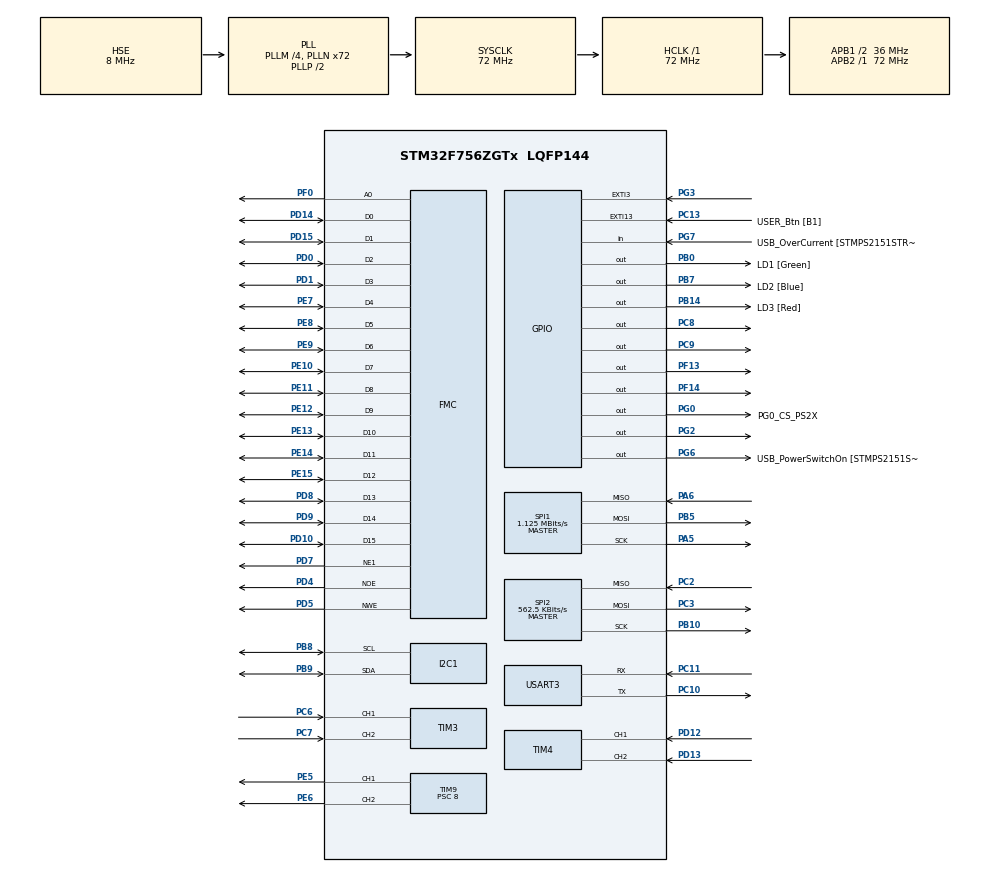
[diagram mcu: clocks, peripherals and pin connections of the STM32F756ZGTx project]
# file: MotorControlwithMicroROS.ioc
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CORTEX_M7.default_mode_Activation=1
Dma.Request0=USART3_RX
Dma.Request1=USART3_TX
Dma.USART3_RX.0.Direction=DMA_PERIPH_TO_MEMORY
Dma.USART3_RX.0.FIFOMode=DMA_FIFOMODE_DISABLE
Dma.USART3_RX.0.Instance=DMA1_Stream1
Dma.USART3_RX.0.MemDataAlignment=DMA_MDATAALIGN_BYTE
Dma.USART3_RX.0.MemInc=DMA_MINC_ENABLE
Dma.USART3_RX.0.Mode=DMA_CIRCULAR
Dma.USART3_RX.0.PeriphDataAlignment=DMA_PDATAALIGN_BYTE
Dma.USART3_RX.0.PeriphInc=DMA_PINC_DISABLE
Dma.USART3_RX.0.Priority=DMA_PRIORITY_VERY_HIGH
Dma.USART3_TX.1.Direction=DMA_MEMORY_TO_PERIPH
Dma.USART3_TX.1.FIFOMode=DMA_FIFOMODE_DISABLE
Dma.USART3_TX.1.Instance=DMA1_Stream3
Dma.USART3_TX.1.MemDataAlignment=DMA_MDATAALIGN_BYTE
Dma.USART3_TX.1.MemInc=DMA_MINC_ENABLE
Dma.USART3_TX.1.Mode=DMA_NORMAL
Dma.USART3_TX.1.PeriphDataAlignment=DMA_PDATAALIGN_BYTE
Dma.USART3_TX.1.PeriphInc=DMA_PINC_DISABLE
Dma.USART3_TX.1.Priority=DMA_PRIORITY_VERY_HIGH
FMC.AddressSetupTime1=1
FMC.BusTurnAroundDuration1=0
FMC.DataSetupTime1=5
FREERTOS.Tasks01=defaultTask,24,3000,StartDefaultTask,Default,NULL,Dynamic,NULL,NULL
FREERTOS.configTOTAL_HEAP_SIZE=61440
I2C1.Timing=0x00808CD2
Mcu.Family=STM32F7
Mcu.Name=STM32F756ZGTx
Mcu.Package=LQFP144
NVIC.DMA1_Stream1_IRQn=true\:5\:0\:false\:false\:true\:true\:false\:true\:true
NVIC.DMA1_Stream3_IRQn=true\:5\:0\:false\:false\:true\:true\:false\:true\:true
NVIC.EXTI3_IRQn=true\:5\:0\:false\:false\:true\:true\:true\:true\:true
NVIC.PriorityGroup=NVIC_PRIORITYGROUP_4
NVIC.TIM6_DAC_IRQn=true\:15\:0\:false\:false\:true\:false\:false\:true\:true
NVIC.TimeBase=TIM6_DAC_IRQn
NVIC.TimeBaseIP=TIM6
NVIC.USART3_IRQn=true\:5\:0\:false\:false\:true\:true\:true\:true\:true
PA13.GPIO_Label=TMS
PA13.Mode=Serial_Wire
PA13.Signal=SYS_JTMS-SWDIO
PA14.GPIO_Label=TCK
PA14.Mode=Serial_Wire
PA14.Signal=SYS_JTCK-SWCLK
PA5.Mode=Full_Duplex_Master
PA5.Signal=SPI1_SCK
PA6.Mode=Full_Duplex_Master
PA6.Signal=SPI1_MISO
PA7.GPIO_Label=RMII_CRS_DV [LAN8742A-CZ-TR_CRS_DV]
PA7.Signal=ETH_CRS_DV
PB0.GPIO_Label=LD1 [Green]
PB0.Signal=GPIO_Output
PB10.Mode=Full_Duplex_Master
PB10.Signal=SPI2_SCK
PB13.GPIO_Label=RMII_TXD1 [LAN8742A-CZ-TR_TXD1]
PB13.Signal=ETH_TXD1
PB14.GPIO_Label=LD3 [Red]
PB14.Signal=GPIO_Output
PB3.GPIO_Label=SW0
PB3.Signal=SYS_JTDO-SWO
PB5.Mode=Full_Duplex_Master
PB5.Signal=SPI1_MOSI
PB7.GPIO_Label=LD2 [Blue]
PB7.Signal=GPIO_Output
PB8.Mode=I2C
PB8.Signal=I2C1_SCL
PB9.Mode=I2C
PB9.Signal=I2C1_SDA
PC1.GPIO_Label=RMII_MDC [LAN8742A-CZ-TR_MDC]
PC1.Signal=ETH_MDC
PC10.Mode=Asynchronous
PC10.Signal=USART3_TX
PC11.Mode=Asynchronous
PC11.Signal=USART3_RX
PC13.GPIO_Label=USER_Btn [B1]
PC13.Signal=GPXTI13
PC14/OSC32_IN.Mode=LSE-External-Oscillator
PC14/OSC32_IN.Signal=RCC_OSC32_IN
PC15/OSC32_OUT.Mode=LSE-External-Oscillator
PC15/OSC32_OUT.Signal=RCC_OSC32_OUT
PC2.Mode=Full_Duplex_Master
PC2.Signal=SPI2_MISO
PC3.Mode=Full_Duplex_Master
PC3.Signal=SPI2_MOSI
PC4.GPIO_Label=RMII_RXD0 [LAN8742A-CZ-TR_RXD0]
PC4.Signal=ETH_RXD0
PC5.GPIO_Label=RMII_RXD1 [LAN8742A-CZ-TR_RXD1]
PC5.Signal=ETH_RXD1
PC6.GPIO_ModeDefaultPP=GPIO_MODE_AF_PP
PC6.GPIO_PuPd=GPIO_NOPULL
PC6.Signal=S_TIM3_CH1
PC7.GPIO_ModeDefaultPP=GPIO_MODE_AF_PP
PC7.GPIO_PuPd=GPIO_NOPULL
PC7.Signal=S_TIM3_CH2
PC8.Signal=GPIO_Output
PC9.Signal=GPIO_Output
PD0.Signal=FMC_D2_DA2
PD1.Signal=FMC_D3_DA3
PD10.Signal=FMC_D15_DA15
PD12.Signal=S_TIM4_CH1
PD13.Signal=S_TIM4_CH2
PD14.Signal=FMC_D0_DA0
PD15.Signal=FMC_D1_DA1
PD4.Signal=FMC_NOE
PD5.Signal=FMC_NWE
PD7.Mode=NorPsramChipSelect1_1
PD7.Signal=FMC_NE1
PD8.Signal=FMC_D13_DA13
PD9.Signal=FMC_D14_DA14
PE10.Signal=FMC_D7_DA7
PE11.Signal=FMC_D8_DA8
PE12.Signal=FMC_D9_DA9
PE13.Signal=FMC_D10_DA10
PE14.Signal=FMC_D11_DA11
PE15.Signal=FMC_D12_DA12
PE5.Signal=S_TIM9_CH1
PE6.Signal=S_TIM9_CH2
PE7.Signal=FMC_D4_DA4
PE8.Signal=FMC_D5_DA5
PE9.Signal=FMC_D6_DA6
PF0.Signal=FMC_A0
PF13.Signal=GPIO_Output
PF14.Signal=GPIO_Output
PG0.GPIO_Label=PG0_CS_PS2X
PG0.GPIO_ModeDefaultOutputPP=GPIO_MODE_OUTPUT_PP
PG0.GPIO_Speed=GPIO_SPEED_FREQ_HIGH
PG0.PinState=GPIO_PIN_SET
PG0.Signal=GPIO_Output
PG11.GPIO_Label=RMII_TX_EN [LAN8742A-CZ-TR_TXEN]
PG11.Signal=ETH_TX_EN
PG2.GPIO_Speed=GPIO_SPEED_FREQ_LOW
PG2.PinState=GPIO_PIN_SET
PG2.Signal=GPIO_Output
PG3.GPIO_ModeDefaultEXTI=GPIO_MODE_IT_FALLING
PG3.GPIO_PuPd=GPIO_PULLUP
PG3.Signal=GPXTI3
PG6.GPIO_Label=USB_PowerSwitchOn [STMPS2151STR_EN]
PG6.Signal=GPIO_Output
PG7.GPIO_Label=USB_OverCurrent [STMPS2151STR_FAULT]
PG7.Signal=GPIO_Input
PH0/OSC_IN.GPIO_Label=MCO [STM32F103CBT6_PA8]
PH0/OSC_IN.Mode=HSE-External-Oscillator
PH0/OSC_IN.Signal=RCC_OSC_IN
PH1/OSC_OUT.Mode=HSE-External-Oscillator
PH1/OSC_OUT.Signal=RCC_OSC_OUT
ProjectManager.HeapSize=0x200
ProjectManager.StackSize=0x400
ProjectManager.TargetToolchain=Makefile
RCC.48MHZClocksFreq_Value=24000000
RCC.AHBFreq_Value=72000000
RCC.APB1CLKDivider=RCC_HCLK_DIV2
RCC.APB1Freq_Value=36000000
RCC.APB1TimFreq_Value=72000000
RCC.APB2Freq_Value=72000000
RCC.APB2TimFreq_Value=72000000
RCC.CortexFreq_Value=72000000
RCC.HCLKFreq_Value=72000000
RCC.HSE_VALUE=8000000
RCC.HSI_VALUE=16000000
RCC.PLLM=4
RCC.PLLMUL=RCC_PLL_MUL9
RCC.PLLN=72
RCC.PLLQ=3
RCC.PLLSourceVirtual=RCC_PLLSOURCE_HSE
RCC.PRESCALERUSB=RCC_USBCLKSOURCE_PLL_DIV1_5
RCC.SYSCLKFreq_VALUE=72000000
RCC.SYSCLKSource=RCC_SYSCLKSOURCE_PLLCLK
RCC.SYSCLKSourceVirtual=RCC_SYSCLKSOURCE_PLLCLK
RCC.USBFreq_Value=48000000
RCC.VCOOutputFreq_Value=144000000
SH.FMC_A0.0=FMC_A0,A0_1
SH.FMC_D0_DA0.0=FMC_D0,16b-d1
SH.FMC_D10_DA10.0=FMC_D10,16b-d1
SH.FMC_D11_DA11.0=FMC_D11,16b-d1
SH.FMC_D12_DA12.0=FMC_D12,16b-d1
SH.FMC_D13_DA13.0=FMC_D13,16b-d1
SH.FMC_D14_DA14.0=FMC_D14,16b-d1
SH.FMC_D15_DA15.0=FMC_D15,16b-d1
SH.FMC_D1_DA1.0=FMC_D1,16b-d1
SH.FMC_D2_DA2.0=FMC_D2,16b-d1
SH.FMC_D3_DA3.0=FMC_D3,16b-d1
SH.FMC_D4_DA4.0=FMC_D4,16b-d1
SH.FMC_D5_DA5.0=FMC_D5,16b-d1
SH.FMC_D6_DA6.0=FMC_D6,16b-d1
SH.FMC_D7_DA7.0=FMC_D7,16b-d1
SH.FMC_D8_DA8.0=FMC_D8,16b-d1
SH.FMC_D9_DA9.0=FMC_D9,16b-d1
SH.FMC_NOE.0=FMC_NOE,Lcd1
SH.FMC_NWE.0=FMC_NWE,Lcd1
SH.S_TIM3_CH1.0=TIM3_CH1,Encoder_Interface
SH.S_TIM3_CH2.0=TIM3_CH2,Encoder_Interface
SH.S_TIM4_CH1.0=TIM4_CH1,Encoder_Interface
SH.S_TIM4_CH2.0=TIM4_CH2,Encoder_Interface
SH.S_TIM9_CH1.0=TIM9_CH1,PWM Generation1 CH1
SH.S_TIM9_CH2.0=TIM9_CH2,PWM Generation2 CH2
SPI1.BaudRatePrescaler=SPI_BAUDRATEPRESCALER_64
SPI1.CalculateBaudRate=1.125 MBits/s
SPI1.DataSize=SPI_DATASIZE_8BIT
SPI1.Direction=SPI_DIRECTION_2LINES
SPI1.Mode=SPI_MODE_MASTER
SPI1.VirtualType=VM_MASTER
SPI2.BaudRatePrescaler=SPI_BAUDRATEPRESCALER_64
SPI2.CLKPhase=SPI_PHASE_2EDGE
SPI2.CLKPolarity=SPI_POLARITY_HIGH
SPI2.CalculateBaudRate=562.5 KBits/s
SPI2.DataSize=SPI_DATASIZE_8BIT
SPI2.Direction=SPI_DIRECTION_2LINES
SPI2.FirstBit=SPI_FIRSTBIT_LSB
SPI2.Mode=SPI_MODE_MASTER
SPI2.VirtualType=VM_MASTER
TIM3.AutoReloadPreload=TIM_AUTORELOAD_PRELOAD_ENABLE
TIM3.EncoderMode=TIM_ENCODERMODE_TI12
TIM3.IC1Filter=6
TIM3.IC2Filter=6
TIM4.AutoReloadPreload=TIM_AUTORELOAD_PRELOAD_ENABLE
TIM4.EncoderMode=TIM_ENCODERMODE_TI12
TIM4.IC1Filter=6
TIM4.IC2Filter=6
TIM9.Channel-PWM\ Generation1\ CH1=TIM_CHANNEL_1
TIM9.Channel-PWM\ Generation2\ CH2=TIM_CHANNEL_2
TIM9.Period=1199
TIM9.Prescaler=8
USART3.VirtualMode-Asynchronous=VM_ASYNC
VP_FREERTOS_VS_CMSIS_V2.Mode=CMSIS_V2
VP_SYS_VS_tim6.Mode=TIM6
VP_TIM9_VS_ClockSourceINT.Mode=Internal
board=NUCLEO-F756ZG

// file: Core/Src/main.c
/* USER CODE BEGIN Header */
/**
  ******************************************************************************
  * @file           : main.c
  * @brief          : Main program body
  ******************************************************************************
  * @attention
  *
  * Copyright (c) 2025 STMicroelectronics.
  * All rights reserved.
  *
  * This software is licensed under terms that can be found in the LICENSE file
  * in the root directory of this software component.
  * If no LICENSE file comes with this software, it is provided AS-IS.
  *
  ******************************************************************************
  */
/* USER CODE END Header */
#include "main.h"
#include "cmsis_os.h"
#include "dma.h"
#include "i2c.h"
#include "spi.h"
#include "tim.h"
#include "usart.h"
#include "gpio.h"
#include "fmc.h"

/* USER CODE BEGIN Includes */
#include "robot_params.h"
#include "encoder.h"
#include "motor.h"
#include "encoder_speed.h"
#include "pid.h"
#include "odometry.h"
#include "ili9341.h"
#include "xpt2046.h"
#include "touch_event.h"
#include "ps2xlib.h"
#include <stdarg.h>
#include <stdio.h>
#include <stdbool.h>

//#include "usb_otg_host.h"
/* USER CODE END Includes */

/* USER CODE BEGIN PTD */
#define min(a,b) (((a)<(b))?(a):(b))
/* USER CODE END PTD */

void SystemClock_Config(void);
static void MPU_Config(void);
void MX_FREERTOS_Init(void);
/* USER CODE BEGIN PFP */
void demoLCD(int i);
void locLCD(void);
unsigned long testFillScreen();
unsigned long testText();
unsigned long testLines(uint16_t color);
unsigned long testFastLines(uint16_t color1, uint16_t color2);
unsigned long testRects(uint16_t color);
unsigned long testFilledRects(uint16_t color1, uint16_t color2);
unsigned long testFilledCircles(uint8_t radius, uint16_t color);
unsigned long testCircles(uint8_t radius, uint16_t color);
unsigned long testTriangles();
unsigned long testFilledTriangles();
unsigned long testRoundRects();
unsigned long testFilledRoundRects();
unsigned long testDrawImage();
/* USER CODE END PFP */

int main(void)
{

  /* MPU Configuration--------------------------------------------------------*/
  MPU_Config();

  /* MCU Configuration--------------------------------------------------------*/

  /* Reset of all peripherals, Initializes the Flash interface and the Systick. */
  HAL_Init();

  /* Configure the system clock */
  SystemClock_Config();

  /* Initialize all configured peripherals */
  MX_GPIO_Init();
  MX_DMA_Init();
  MX_I2C1_Init();
  MX_USART3_UART_Init();
  MX_TIM3_Init();
  MX_TIM9_Init();
  MX_FMC_Init();
  MX_SPI1_Init();
  MX_SPI2_Init();
  MX_TIM4_Init();
  /* USER CODE BEGIN 2 */
  //HAL_NVIC_DisableIRQ(TIM6_DAC_IRQn);  //tam dung ngat timer 6 de setup
  //MX_USB_OTG_FS_HCD_Init();
  //MX_USB_HOST_Init();
  //HAL_NVIC_EnableIRQ(TIM6_DAC_IRQn);   //bat lai ngat timer 6

  HAL_GPIO_WritePin(GPIOC, GPIO_PIN_8, GPIO_PIN_RESET); // RESET = 0
  HAL_Delay(10);
  HAL_GPIO_WritePin(GPIOC, GPIO_PIN_8, GPIO_PIN_SET);   // RESET = 1
  HAL_Delay(120);

  //Initialize touch event
  //Touch_Init_Lib();

  Encoder_Reset(ENCODER_1);
  Encoder_Reset(ENCODER_2);
  Encoder_Init();
  EncoderSpeed_Init();
  Motor_Init();

  //int32_t PID_sampletime = 5;

  PID(&PosPID1, &CurPos1, &PosPIDOut1, &DesiredPos1, Kp1, Ki1, Kd1, _PID_P_ON_E, _PID_CD_DIRECT);
  PID_SetMode(&PosPID1, _PID_MODE_AUTOMATIC);
  PID_SetSampleTime(&PosPID1, MOTORCONTROL_PERIOD_MS);
  PID_SetOutputLimits(&PosPID1, -MOTOR_SPEED_MAX, MOTOR_SPEED_MAX);

  PID(&PosPID2, &CurPos2, &PosPIDOut2, &DesiredPos2, Kp2, Ki2, Kd2, _PID_P_ON_E, _PID_CD_DIRECT);
  PID_SetMode(&PosPID2, _PID_MODE_AUTOMATIC);
  PID_SetSampleTime(&PosPID2, MOTORCONTROL_PERIOD_MS);
  PID_SetOutputLimits(&PosPID2, -MOTOR_SPEED_MAX, MOTOR_SPEED_MAX);

  PID(&SpeedPID1, &CurSpeed1, &SpeedPIDOut1, &DesiredSpeed1, Kp1, Ki1, Kd1, _PID_P_ON_E, _PID_CD_DIRECT);
  PID_SetMode(&SpeedPID1, _PID_MODE_AUTOMATIC);
  PID_SetSampleTime(&SpeedPID1, MOTORCONTROL_PERIOD_MS);
  PID_SetOutputLimits(&SpeedPID1, -MOTOR_SPEED_MAX, MOTOR_SPEED_MAX);

  PID(&SpeedPID2, &CurSpeed2, &SpeedPIDOut2, &DesiredSpeed2, Kp2, Ki2, Kd2, _PID_P_ON_E, _PID_CD_DIRECT);
  PID_SetMode(&SpeedPID2, _PID_MODE_AUTOMATIC);
  PID_SetSampleTime(&SpeedPID2, MOTORCONTROL_PERIOD_MS);
  PID_SetOutputLimits(&SpeedPID2, -MOTOR_SPEED_MAX, MOTOR_SPEED_MAX);

  PID_Init(&PosPID1); PID_Init(&PosPID2);
  PID_Init(&SpeedPID1); PID_Init(&SpeedPID2);

  //Here start to display LCD
  lcdInit();
  int i = 1;
  for (i=0;i<=0;i++)
  {
	  //demoLCD(i);
	  locLCD();

  }

//  const char test_msg[] = "USART2 VCP OK\r\n";
//  while (1)
//  {
//	  HAL_StatusTypeDef st = HAL_UART_Transmit(&huart2,
//	                                           (uint8_t*)test_msg,
//	                                           sizeof(test_msg)-1,
//	                                           10);
//
//    HAL_Delay(500);   // gửi mỗi 500 ms
//  }
  /* USER CODE END 2 */

  /* Init scheduler */
  osKernelInitialize();  /* Call init function for freertos objects (in cmsis_os2.c) */
  MX_FREERTOS_Init();

  /* Start scheduler */
  osKernelStart();

  /* We should never get here as control is now taken by the scheduler */

  /* Infinite loop */
  while (1)
  {

  }
}

void SystemClock_Config(void)
{
  RCC_OscInitTypeDef RCC_OscInitStruct = {0};
  RCC_ClkInitTypeDef RCC_ClkInitStruct = {0};

  /** Configure LSE Drive Capability
  */
  HAL_PWR_EnableBkUpAccess();

  /** Configure the main internal regulator output voltage
  */
  __HAL_RCC_PWR_CLK_ENABLE();
  __HAL_PWR_VOLTAGESCALING_CONFIG(PWR_REGULATOR_VOLTAGE_SCALE3);

  /** Initializes the RCC Oscillators according to the specified parameters
  * in the RCC_OscInitTypeDef structure.
  */
  RCC_OscInitStruct.OscillatorType = RCC_OSCILLATORTYPE_HSE;
  RCC_OscInitStruct.HSEState = RCC_HSE_ON;
  RCC_OscInitStruct.PLL.PLLState = RCC_PLL_ON;
  RCC_OscInitStruct.PLL.PLLSource = RCC_PLLSOURCE_HSE;
  RCC_OscInitStruct.PLL.PLLM = 4;
  RCC_OscInitStruct.PLL.PLLN = 72;
  RCC_OscInitStruct.PLL.PLLP = RCC_PLLP_DIV2;
  RCC_OscInitStruct.PLL.PLLQ = 3;
  if (HAL_RCC_OscConfig(&RCC_OscInitStruct) != HAL_OK)
  {
    Error_Handler();
  }

  /** Initializes the CPU, AHB and APB buses clocks
  */
  RCC_ClkInitStruct.ClockType = RCC_CLOCKTYPE_HCLK|RCC_CLOCKTYPE_SYSCLK
                              |RCC_CLOCKTYPE_PCLK1|RCC_CLOCKTYPE_PCLK2;
  RCC_ClkInitStruct.SYSCLKSource = RCC_SYSCLKSOURCE_PLLCLK;
  RCC_ClkInitStruct.AHBCLKDivider = RCC_SYSCLK_DIV1;
  RCC_ClkInitStruct.APB1CLKDivider = RCC_HCLK_DIV2;
  RCC_ClkInitStruct.APB2CLKDivider = RCC_HCLK_DIV1;

  if (HAL_RCC_ClockConfig(&RCC_ClkInitStruct, FLASH_LATENCY_2) != HAL_OK)
  {
    Error_Handler();
  }
}

/* USER CODE BEGIN 4 */
void MPU_Config(void)
{
  MPU_Region_InitTypeDef MPU_InitStruct = {0};

  HAL_MPU_Disable();

  // -------- Region0: default deny (giữ giống bạn) --------
  MPU_InitStruct.Enable           = MPU_REGION_ENABLE;
  MPU_InitStruct.Number           = MPU_REGION_NUMBER0;
  MPU_InitStruct.BaseAddress      = 0x00000000;
  MPU_InitStruct.Size             = MPU_REGION_SIZE_4GB;
  MPU_InitStruct.SubRegionDisable = 0x87; // như bạn
  MPU_InitStruct.TypeExtField     = MPU_TEX_LEVEL0;
  MPU_InitStruct.AccessPermission = MPU_REGION_NO_ACCESS;
  MPU_InitStruct.DisableExec      = MPU_INSTRUCTION_ACCESS_DISABLE;
  MPU_InitStruct.IsShareable      = MPU_ACCESS_SHAREABLE;
  MPU_InitStruct.IsCacheable      = MPU_ACCESS_NOT_CACHEABLE;
  MPU_InitStruct.IsBufferable     = MPU_ACCESS_NOT_BUFFERABLE;
  HAL_MPU_ConfigRegion(&MPU_InitStruct);

  // -------- Region1: allow FMC registers @0xA0000000 --------
  MPU_InitStruct.Enable           = MPU_REGION_ENABLE;
  MPU_InitStruct.Number           = MPU_REGION_NUMBER1;
  MPU_InitStruct.BaseAddress      = 0xA0000000;
  MPU_InitStruct.Size             = MPU_REGION_SIZE_1MB;   // đủ cho FMC regs
  MPU_InitStruct.SubRegionDisable = 0x00;
  MPU_InitStruct.TypeExtField     = MPU_TEX_LEVEL0;
  MPU_InitStruct.AccessPermission = MPU_REGION_FULL_ACCESS;
  MPU_InitStruct.DisableExec      = MPU_INSTRUCTION_ACCESS_DISABLE;
  MPU_InitStruct.IsShareable      = MPU_ACCESS_SHAREABLE;
  MPU_InitStruct.IsCacheable      = MPU_ACCESS_NOT_CACHEABLE;
  MPU_InitStruct.IsBufferable     = MPU_ACCESS_BUFFERABLE; // peripheral/device
  HAL_MPU_ConfigRegion(&MPU_InitStruct);

  // -------- Region2: allow FMC Bank1 mapped @0x60000000 (LCD) --------
  MPU_InitStruct.Enable           = MPU_REGION_ENABLE;
  MPU_InitStruct.Number           = MPU_REGION_NUMBER2;
  MPU_InitStruct.BaseAddress      = 0x60000000;
  MPU_InitStruct.Size             = MPU_REGION_SIZE_64MB;  // Bank1 window (thường dùng)
  MPU_InitStruct.SubRegionDisable = 0x00;
  MPU_InitStruct.TypeExtField     = MPU_TEX_LEVEL0;
  MPU_InitStruct.AccessPermission = MPU_REGION_FULL_ACCESS;
  MPU_InitStruct.DisableExec      = MPU_INSTRUCTION_ACCESS_DISABLE;
  MPU_InitStruct.IsShareable      = MPU_ACCESS_SHAREABLE;
  MPU_InitStruct.IsCacheable      = MPU_ACCESS_NOT_CACHEABLE;
  MPU_InitStruct.IsBufferable     = MPU_ACCESS_BUFFERABLE;
  HAL_MPU_ConfigRegion(&MPU_InitStruct);

  HAL_MPU_Enable(MPU_PRIVILEGED_DEFAULT);
}

void demoLCD(int i)
{
	lcdSetOrientation(i % 4);

	uint32_t t = testFillScreen();
	lcdSetTextFont(&Font16);
	lcdSetCursor(0, lcdGetHeight() - lcdGetTextFont()->Height - 1);
	lcdSetTextColor(COLOR_WHITE, COLOR_BLACK);
	lcdPrintf("Time: %4lu ms", t);
	HAL_Delay(2000);

	t = HAL_GetTick();
	lcdTest();
	lcdSetTextFont(&Font16);
	lcdSetCursor(0, lcdGetHeight() - lcdGetTextFont()->Height - 1);
	lcdSetTextColor(COLOR_WHITE, COLOR_BLACK);
	lcdPrintf("Time: %4lu ms", HAL_GetTick() - t);
	HAL_Delay(2000);

	t = testText();
	lcdSetTextFont(&Font16);
	lcdSetCursor(0, lcdGetHeight() - lcdGetTextFont()->Height - 1);
	lcdSetTextColor(COLOR_WHITE, COLOR_BLACK);
	lcdPrintf("Time: %4lu ms", t);
	HAL_Delay(2000);

	lcdSetTextFont(&Font16);
	lcdSetCursor(0, lcdGetHeight() - lcdGetTextFont()->Height - 1);
	lcdSetTextColor(COLOR_WHITE, COLOR_BLACK);
	lcdPrintf("Time: %4lu ms", testLines(COLOR_CYAN));
	HAL_Delay(2000);

	lcdSetTextFont(&Font16);
	lcdSetCursor(0, lcdGetHeight() - lcdGetTextFont()->Height - 1);
	lcdSetTextColor(COLOR_WHITE, COLOR_BLACK);
	lcdPrintf("Time: %4lu ms", testFastLines(COLOR_RED, COLOR_BLUE));
	HAL_Delay(2000);

	lcdSetTextFont(&Font16);
	lcdSetCursor(0, lcdGetHeight() - lcdGetTextFont()->Height - 1);
	lcdSetTextColor(COLOR_WHITE, COLOR_BLACK);
	lcdPrintf("Time: %4lu ms", testRects(COLOR_GREEN));
	HAL_Delay(2000);

	lcdSetTextFont(&Font16);
	lcdSetCursor(0, lcdGetHeight() - lcdGetTextFont()->Height - 1);
	lcdSetTextColor(COLOR_WHITE, COLOR_BLACK);
	lcdPrintf("Time: %4lu ms", testFilledRects(COLOR_YELLOW, COLOR_MAGENTA));
	HAL_Delay(2000);

	lcdSetTextFont(&Font16);
	lcdSetCursor(0, lcdGetHeight() - lcdGetTextFont()->Height - 1);
	lcdSetTextColor(COLOR_WHITE, COLOR_BLACK);
	lcdPrintf("Time: %4lu ms", testFilledCircles(10, COLOR_MAGENTA));
	HAL_Delay(2000);

	lcdSetTextFont(&Font16);
	lcdSetCursor(0, lcdGetHeight() - lcdGetTextFont()->Height - 1);
	lcdSetTextColor(COLOR_WHITE, COLOR_BLACK);
	lcdPrintf("Time: %4lu ms", testCircles(10, COLOR_WHITE));
	HAL_Delay(2000);

	lcdSetTextFont(&Font16);
	lcdSetCursor(0, lcdGetHeight() - lcdGetTextFont()->Height - 1);
	lcdSetTextColor(COLOR_WHITE, COLOR_BLACK);
	lcdPrintf("Time: %4lu ms", testTriangles());
	HAL_Delay(2000);

	lcdSetTextFont(&Font16);
	lcdSetCursor(0, lcdGetHeight() - lcdGetTextFont()->Height - 1);
	lcdSetTextColor(COLOR_WHITE, COLOR_BLACK);
	lcdPrintf("Time: %4lu ms", testFilledTriangles());
	HAL_Delay(2000);

	lcdSetTextFont(&Font16);
	lcdSetCursor(0, lcdGetHeight() - lcdGetTextFont()->Height - 1);
	lcdSetTextColor(COLOR_WHITE, COLOR_BLACK);
	lcdPrintf("Time: %4lu ms", testRoundRects());
	HAL_Delay(2000);

	lcdSetTextFont(&Font16);
	lcdSetCursor(0, lcdGetHeight() - lcdGetTextFont()->Height - 1);
	lcdSetTextColor(COLOR_WHITE, COLOR_BLACK);
	lcdPrintf("Time: %4lu ms", testFilledRoundRects());
	HAL_Delay(2000);

	lcdSetTextFont(&Font16);
	lcdSetCursor(0, lcdGetHeight() - lcdGetTextFont()->Height - 1);
	lcdSetTextColor(COLOR_WHITE, COLOR_BLACK);
	lcdPrintf("Time: %4lu ms", testDrawImage());
	HAL_Delay(2000);
}

typedef struct { uint16_t x,y,w,h; } Rect_t;

static Rect_t g_val_pwm1, g_val_pwm2, g_val_enc1, g_val_enc2;
static Rect_t g_val_v1, g_val_v2;
static Rect_t g_val_x, g_val_y, g_val_yaw;

static uint16_t g_charW = 8, g_fontH = 12, g_pad = 6;

void locLCD(void)
{
    lcdSetOrientation(LCD_ORIENTATION_LANDSCAPE);
    lcdFillRGB(COLOR_BLACK);
    lcdSetTextFont(&Font12);

    uint16_t W = lcdGetWidth();
    uint16_t H = lcdGetHeight();

    uint16_t fontH = lcdGetTextFont()->Height;
    uint16_t charW = lcdGetTextFont()->Width;   // nếu lỗi -> đổi thành 8

    // ===== Grid =====
    uint16_t M  = 6;
    uint16_t GX = M;
    uint16_t GY = 22;
    uint16_t GW = W - 2*M;
    uint16_t GH = H - GY - M;

    uint16_t CW = GW / 3;
    uint16_t RH = GH / 4;
    uint16_t P  = 6;
    g_fontH = fontH;
    g_charW = (charW == 0) ? 8 : charW;
    g_pad   = P;

    #define STORE_VALUE_RECT(_rect, cx, cy, cw, ch) do {                          \
        int16_t _y0 = (int16_t)(cy) + (int16_t)(((ch) - 2*(int16_t)fontH)/2);     \
        if (_y0 < (int16_t)(cy)+P) _y0 = (int16_t)(cy)+P;                         \
        (_rect).x = (uint16_t)((cx) + 1);                                         \
        (_rect).y = (uint16_t)(_y0 + (int16_t)fontH);                             \
        (_rect).w = (uint16_t)((cw) - 2);                                         \
        (_rect).h = (uint16_t)(fontH);                                            \
    } while(0)
    // ===== Header =====
    lcdSetTextColor(COLOR_YELLOW, COLOR_BLACK);
    lcdSetCursor(M, 4);
    lcdPrintf("Robomango Zackon");

    // ===== Draw grid =====
    lcdSetTextColor(COLOR_WHITE, COLOR_BLACK);
    lcdDrawRect(GX, GY, GW, GH, COLOR_WHITE);
    lcdDrawVLine(GX + CW,   GY, GY + GH, COLOR_WHITE);
    lcdDrawVLine(GX + 2*CW, GY, GY + GH, COLOR_WHITE);
    for (int r = 1; r < 4; r++)
        lcdDrawHLine(GX, GX + GW, GY + r*RH, COLOR_WHITE);

    #define CELL_X(c) (GX + (c)*CW)
    #define CELL_Y(r) (GY + (r)*RH)
    #define MAX_CHARS(_w)  ((int)(((_w) - 2*P) / charW))

    // ===== In 2 dòng, CẢ 2 dòng đều căn giữa + clip không tràn =====
    #define PRINT_2LINES_CENTER(cx,cy,cw,ch,l1,l2,color,bg) do {           \
        int m = MAX_CHARS(cw); if (m < 1) m = 1;                           \
        int len1 = (int)strlen(l1); if (len1 > m) len1 = m;                \
        int len2 = (int)strlen(l2); if (len2 > m) len2 = m;                \
        int w1 = len1 * (int)charW;                                        \
        int w2 = len2 * (int)charW;                                        \
        int wMax = (w1 > w2) ? w1 : w2;                                    \
        int16_t x = (int16_t)(cx) + (int16_t)((cw) - wMax)/2;              \
        int16_t y = (int16_t)(cy) + (int16_t)((ch) - 2*(int16_t)fontH)/2;  \
        if (x < (int16_t)(cx)+P) x = (int16_t)(cx)+P;                      \
        if (y < (int16_t)(cy)+P) y = (int16_t)(cy)+P;                      \
        lcdSetTextColor(color, bg);                                        \
        lcdSetCursor((unsigned short)x, (unsigned short)y);                \
        lcdPrintf("%.*s", len1, l1);                                       \
        lcdSetCursor((unsigned short)x, (unsigned short)(y + fontH));      \
        lcdPrintf("%.*s", len2, l2);                                       \
    } while(0)

    // ===== Button: 1 dòng căn giữa + clip =====
    #define PRINT_CENTER_1LINE(cx,cy,cw,ch,text,color,bg) do {             \
        int m = MAX_CHARS(cw); if (m < 1) m = 1;                           \
        int len = (int)strlen(text); if (len > m) len = m;                 \
        int16_t x = (int16_t)(cx) + (int16_t)((cw) - len*(int)charW)/2;    \
        int16_t y = (int16_t)(cy) + (int16_t)((ch) - (int16_t)fontH)/2 + 1;\
        if (x < (int16_t)(cx)+P) x = (int16_t)(cx)+P;                      \
        if (y < (int16_t)(cy)+P) y = (int16_t)(cy)+P;                      \
        lcdSetTextColor(color, bg);                                        \
        lcdSetCursor((unsigned short)x, (unsigned short)y);                \
        lcdPrintf("%.*s", len, text);                                      \
    } while(0)

    // ===== Cột 1 (tất cả CENTER) =====
    PRINT_2LINES_CENTER(CELL_X(0), CELL_Y(0), CW, RH, "PWM1", "0.0",  COLOR_CYAN, COLOR_BLACK);
    STORE_VALUE_RECT(g_val_pwm1, CELL_X(0), CELL_Y(0), CW, RH);

    PRINT_2LINES_CENTER(CELL_X(0), CELL_Y(1), CW, RH, "PWM2", "0.0",  COLOR_CYAN, COLOR_BLACK);
    STORE_VALUE_RECT(g_val_pwm2, CELL_X(0), CELL_Y(1), CW, RH);

    PRINT_2LINES_CENTER(CELL_X(0), CELL_Y(2), CW, RH, "Enc1", "0.0", COLOR_CYAN, COLOR_BLACK);
    STORE_VALUE_RECT(g_val_enc1, CELL_X(0), CELL_Y(2), CW, RH);

    PRINT_2LINES_CENTER(CELL_X(0), CELL_Y(3), CW, RH, "Enc2", "0.0", COLOR_CYAN, COLOR_BLACK);
    STORE_VALUE_RECT(g_val_enc2, CELL_X(0), CELL_Y(3), CW, RH);

    // ===== Cột 2 =====
    PRINT_2LINES_CENTER(CELL_X(1), CELL_Y(0), CW, RH, "V1", "0.0", COLOR_CYAN, COLOR_BLACK);
    STORE_VALUE_RECT(g_val_v1, CELL_X(1), CELL_Y(0), CW, RH);

    PRINT_2LINES_CENTER(CELL_X(1), CELL_Y(1), CW, RH, "V2", "0.0", COLOR_CYAN, COLOR_BLACK);
    STORE_VALUE_RECT(g_val_v2, CELL_X(1), CELL_Y(1), CW, RH);

    // Button Figure
    {
        uint16_t bx = CELL_X(1)+4, by = CELL_Y(2)+4;
        uint16_t bw = CW-8, bh = RH-8;
        lcdFillRect(bx, by, bw, bh, COLOR_DARKGREY);
        lcdDrawRect(bx, by, bw, bh, COLOR_WHITE);
        PRINT_CENTER_1LINE(bx, by, bw, bh, "Figure", COLOR_DARKGREY, COLOR_DARKGREY);
    }

    // Button Controller
    {
        uint16_t bx = CELL_X(1)+4, by = CELL_Y(3)+4;
        uint16_t bw = CW-8, bh = RH-8;
        lcdFillRect(bx, by, bw, bh, COLOR_DARKGREY);
        lcdDrawRect(bx, by, bw, bh, COLOR_WHITE);
        PRINT_CENTER_1LINE(bx, by, bw, bh, "Controller", COLOR_WHITE, COLOR_DARKGREY);
    }

    // ===== Cột 3 =====
    PRINT_2LINES_CENTER(CELL_X(2), CELL_Y(0), CW, RH, "Odom X", "0.0", COLOR_CYAN, COLOR_BLACK);
    STORE_VALUE_RECT(g_val_x, CELL_X(2), CELL_Y(0), CW, RH);

    PRINT_2LINES_CENTER(CELL_X(2), CELL_Y(1), CW, RH, "Odom Y", "0.0", COLOR_CYAN, COLOR_BLACK);
    STORE_VALUE_RECT(g_val_y, CELL_X(2), CELL_Y(1), CW, RH);

    PRINT_2LINES_CENTER(CELL_X(2), CELL_Y(2), CW, RH, "Yaw",   "0.0", COLOR_CYAN, COLOR_BLACK);
    STORE_VALUE_RECT(g_val_yaw, CELL_X(2), CELL_Y(2), CW, RH);

    // Button Setting PID
    {
        uint16_t bx = CELL_X(2)+4, by = CELL_Y(3)+4;
        uint16_t bw = CW-8, bh = RH-8;
        lcdFillRect(bx, by, bw, bh, COLOR_DARKGREY);
        lcdDrawRect(bx, by, bw, bh, COLOR_WHITE);
        PRINT_CENTER_1LINE(bx, by, bw, bh, "Setting PID", COLOR_WHITE, COLOR_DARKGREY);
    }

    #undef PRINT_CENTER_1LINE
    #undef PRINT_2LINES_CENTER
    #undef MAX_CHARS
    #undef CELL_X
    #undef CELL_Y
	#undef STORE_VALUE_RECT

}

static void drawValueInRect(const Rect_t* r, const char* val, uint16_t color, uint16_t bg)
{
    // clear đúng 1 dòng value
    lcdFillRect(r->x, r->y, r->w, r->h, bg);

    int maxChars = (int)((r->w - 2*g_pad) / g_charW);
    if (maxChars < 1) maxChars = 1;

    int len = (int)strlen(val);
    if (len > maxChars) len = maxChars;

    int16_t x = (int16_t)r->x + (int16_t)((r->w - len*(int)g_charW)/2);
    int16_t y = (int16_t)r->y;

    lcdSetTextColor(color, bg);
    lcdSetCursor((unsigned short)x, (unsigned short)y);
    lcdPrintf("%.*s", len, val);
}

unsigned long testFillScreen()
{
	unsigned long start = HAL_GetTick(), t = 0;
	lcdFillRGB(COLOR_BLACK);
	t += HAL_GetTick() - start;
	lcdSetCursor(0, 0);
	lcdSetTextFont(&Font24);
	lcdSetTextColor(COLOR_WHITE, COLOR_BLACK);
	lcdPrintf("BLACK");
	HAL_Delay(1000);
	start = HAL_GetTick();
	lcdFillRGB(COLOR_RED);
	t += HAL_GetTick() - start;
	lcdSetCursor(0, 0);
	lcdSetTextFont(&Font24);
	lcdSetTextColor(COLOR_WHITE, COLOR_BLACK);
	lcdPrintf("RED");
	HAL_Delay(1000);
	start = HAL_GetTick();
	lcdFillRGB(COLOR_GREEN);
	t += HAL_GetTick() - start;
	lcdSetCursor(0, 0);
	lcdSetTextFont(&Font24);
	lcdSetTextColor(COLOR_WHITE, COLOR_BLACK);
	lcdPrintf("GREEN");
	HAL_Delay(1000);
	start = HAL_GetTick();
	lcdFillRGB(COLOR_BLUE);
	t += HAL_GetTick() - start;
	lcdSetCursor(0, 0);
	lcdSetTextFont(&Font24);
	lcdSetTextColor(COLOR_WHITE, COLOR_BLACK);
	lcdPrintf("BLUE");
	HAL_Delay(1000);
	start = HAL_GetTick();
	lcdFillRGB(COLOR_BLACK);
	return t += HAL_GetTick() - start;
}

	unsigned long testText()
	{
		lcdFillRGB(COLOR_BLACK);
		unsigned long start = HAL_GetTick();
		lcdSetCursor(0, 0);
		lcdSetTextColor(COLOR_WHITE, COLOR_BLACK);
		lcdSetTextFont(&Font8);
		lcdPrintf("Hello World!\r\n");
		lcdSetTextColor(COLOR_YELLOW, COLOR_BLACK);
		lcdSetTextFont(&Font12);
		lcdPrintf("%i\r\n", 1234567890);
		lcdSetTextColor(COLOR_RED, COLOR_BLACK);
		lcdSetTextFont(&Font12);
		lcdPrintf("%#X\r\n", 0xDEADBEEF);
		lcdPrintf("\r\n");
		lcdSetTextColor(COLOR_GREEN, COLOR_BLACK);
		lcdSetTextFont(&Font20);
		lcdPrintf("Groop\r\n");
		lcdSetTextFont(&Font12);
		lcdPrintf("I implore thee,\r\n");
		lcdSetTextFont(&Font12);
		lcdPrintf("my foonting turlingdromes.\r\n");
		lcdPrintf("And hooptiously drangle me\r\n");
		lcdPrintf("with crinkly bindlewurdles,\r\n");
		lcdPrintf("Or I will rend thee\r\n");
		lcdPrintf("in the gobberwarts\r\n");
		lcdPrintf("with my blurglecruncheon,\r\n");
		lcdPrintf("see if I don't!\r\n");
		return HAL_GetTick() - start;
	}

unsigned long testLines(uint16_t color)
{
  unsigned long start, t;
  int           x1, y1, x2, y2,
                w = lcdGetWidth(),
                h = lcdGetHeight();

  lcdFillRGB(COLOR_BLACK);

  x1 = y1 = 0;
  y2    = h - 1;
  start = HAL_GetTick();
  for(x2 = 0; x2 < w; x2 += 6) lcdDrawLine(x1, y1, x2, y2, color);
  x2 = w - 1;
  for(y2 = 0; y2 < h; y2 += 6) lcdDrawLine(x1, y1, x2, y2, color);
  t = HAL_GetTick() - start; // fillScreen doesn't count against timing

  HAL_Delay(1000);
  lcdFillRGB(COLOR_BLACK);

  x1 = w - 1;
  y1 = 0;
  y2 = h - 1;

  start = HAL_GetTick();

  for(x2 = 0; x2 < w; x2 += 6) lcdDrawLine(x1, y1, x2, y2, color);
  x2 = 0;
  for(y2 = 0; y2 < h; y2 += 6) lcdDrawLine(x1, y1, x2, y2, color);
  t += HAL_GetTick() - start;

  HAL_Delay(1000);
  lcdFillRGB(COLOR_BLACK);

  x1 = 0;
  y1 = h - 1;
  y2 = 0;
  start = HAL_GetTick();

  for(x2 = 0; x2 < w; x2 += 6) lcdDrawLine(x1, y1, x2, y2, color);
  x2 = w - 1;
  for(y2 = 0; y2 < h; y2 += 6) lcdDrawLine(x1, y1, x2, y2, color);
  t += HAL_GetTick() - start;

  HAL_Delay(1000);
  lcdFillRGB(COLOR_BLACK);

  x1 = w - 1;
  y1 = h - 1;
  y2 = 0;

  start = HAL_GetTick();

  for(x2 = 0; x2 < w; x2 += 6) lcdDrawLine(x1, y1, x2, y2, color);
  x2 = 0;
  for(y2 = 0; y2 < h; y2 += 6) lcdDrawLine(x1, y1, x2, y2, color);

  return t += HAL_GetTick() - start;
}

unsigned long testFastLines(uint16_t color1, uint16_t color2)
{
  unsigned long start;
  int x, y, w = lcdGetWidth(), h = lcdGetHeight();

  lcdFillRGB(COLOR_BLACK);
  start = HAL_GetTick();
  for(y = 0; y < h; y += 5) lcdDrawHLine(0, w, y, color1);
  for(x = 0; x < w; x += 5) lcdDrawVLine(x, 0, h, color2);

  return HAL_GetTick() - start;
}

unsigned long testRects(uint16_t color)
{
  unsigned long start;
  int n, i, i2,
      cx = lcdGetWidth()  / 2,
      cy = lcdGetHeight() / 2;

  lcdFillRGB(COLOR_BLACK);
  n = min(lcdGetWidth(), lcdGetHeight());
  start = HAL_GetTick();
  for(i = 2; i < n; i += 6)
  {
    i2 = i / 2;
    lcdDrawRect(cx - i2, cy - i2, i, i, color);
  }

  return HAL_GetTick() - start;
}

unsigned long testFilledRects(uint16_t color1, uint16_t color2)
{
  unsigned long start, t = 0;
  int n, i, i2,
      cx = lcdGetWidth() / 2 - 1,
      cy = lcdGetHeight() / 2 - 1;

  lcdFillRGB(COLOR_BLACK);
  n = min(lcdGetWidth(), lcdGetHeight());

  for(i = n; i > 0; i -= 6)
  {
    i2 = i / 2;
    start = HAL_GetTick();
    lcdFillRect(cx-i2, cy-i2, i, i, color1);
    t    += HAL_GetTick() - start;
    // Outlines are not included in timing results
    lcdDrawRect(cx-i2, cy-i2, i, i, color1);
  }

  return t;
}

unsigned long testFilledCircles(uint8_t radius, uint16_t color)
{
  unsigned long start;
  int x, y, w = lcdGetWidth(), h = lcdGetHeight(), r2 = radius * 2;

  lcdFillRGB(COLOR_BLACK);
  start = HAL_GetTick();
  for(x = radius; x < w; x += r2)
  {
    for(y = radius; y < h; y += r2)
    {
      lcdFillCircle(x, y, radius, color);
    }
  }

  return HAL_GetTick() - start;
}

unsigned long testCircles(uint8_t radius, uint16_t color)
{
  unsigned long start;
  int x, y, r2 = radius * 2,
      w = lcdGetWidth()  + radius,
      h = lcdGetHeight() + radius;

  // Screen is not cleared for this one -- this is
  // intentional and does not affect the reported time.
  start = HAL_GetTick();
  for(x = 0; x < w; x += r2)
  {
    for(y = 0; y < h; y += r2)
    {
      lcdDrawCircle(x, y, radius, color);
    }
  }

  return HAL_GetTick() - start;
}

unsigned long testTriangles()
{
  unsigned long start;
  int n, i, cx = lcdGetWidth() / 2 - 1,
            cy = lcdGetHeight() / 2 - 1;

  lcdFillRGB(COLOR_BLACK);
  n = min(cx, cy);
  start = HAL_GetTick();
  for(i = 0; i < n; i += 5)
  {
    lcdDrawTriangle(
      cx    , cy - i, // peak
      cx - i, cy + i, // bottom left
      cx + i, cy + i, // bottom right
      lcdColor565(i, i, i));
  }

  return HAL_GetTick() - start;
}

unsigned long testFilledTriangles()
{
  unsigned long start, t = 0;
  int i, cx = lcdGetWidth() / 2 - 1,
         cy = lcdGetHeight() / 2 - 1;

  lcdFillRGB(COLOR_BLACK);
  for(i = min(cx, cy); i > 10; i -= 5)
  {
    start = HAL_GetTick();
    lcdFillTriangle(cx, cy - i, cx - i, cy + i, cx + i, cy + i, lcdColor565(0, i*10, i*10));
    t += HAL_GetTick() - start;
    lcdFillTriangle(cx, cy - i, cx - i, cy + i, cx + i, cy + i, lcdColor565(i*10, i*10, 0));
  }

  return t;
}

unsigned long testRoundRects()
{
  unsigned long start;
  int w, i, i2,
      cx = lcdGetWidth() / 2 - 1,
      cy = lcdGetHeight() / 2 - 1;

  lcdFillRGB(COLOR_BLACK);
  w = lcdGetWidth(), lcdGetHeight();
  start = HAL_GetTick();
  for(i = 0; i < w; i += 6)
  {
    i2 = i / 2;
    lcdDrawRoundRect(cx-i2, cy-i2, i, i, i/8, lcdColor565(i, 0, 0));
  }

  return HAL_GetTick() - start;
}

unsigned long testFilledRoundRects()
{
  unsigned long start;
  int i, i2,
      cx = lcdGetWidth()  / 2 - 1,
      cy = lcdGetHeight() / 2 - 1;

  lcdFillRGB(COLOR_BLACK);
  start = HAL_GetTick();
  for(i = min(lcdGetWidth(), lcdGetHeight()); i > 20; i -=6 )
  {
    i2 = i / 2;
    lcdFillRoundRect(cx - i2, cy - i2, i, i, i / 8, lcdColor565(0, i, 0));
  }

  return HAL_GetTick() - start;
}

unsigned long testDrawImage()
{
	unsigned long start;

	lcdFillRGB(COLOR_BLACK);
	start = HAL_GetTick();
	if (lcdGetOrientation() == LCD_ORIENTATION_LANDSCAPE || lcdGetOrientation() == LCD_ORIENTATION_LANDSCAPE_MIRROR)
	{
		lcdDrawImage((lcdGetWidth() - bmSTLogo.xSize) / 2, 0, &bmSTLogo);
	}
	else
	{
		lcdDrawImage(0, (lcdGetHeight() - bmSTLogo.ySize) / 2, &bmSTLogo);
	}
	return HAL_GetTick() - start;
}
/* USER CODE END 4 */

void HAL_TIM_PeriodElapsedCallback(TIM_HandleTypeDef *htim)
{
  if (htim->Instance == TIM6)
  {
    HAL_IncTick();
  }
}

void Error_Handler(void)
{
  __disable_irq();
  while (1)
  {
  }
}

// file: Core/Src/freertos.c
/* USER CODE BEGIN Header */
/**
  ******************************************************************************
  * File Name          : freertos.c
  * Description        : Code for freertos applications
  ******************************************************************************
  * @attention
  *
  * Copyright (c) 2025 STMicroelectronics.
  * All rights reserved.
  *
  * This software is licensed under terms that can be found in the LICENSE file
  * in the root directory of this software component.
  * If no LICENSE file comes with this software, it is provided AS-IS.
  *
  ******************************************************************************
  */
/* USER CODE END Header */

#include "FreeRTOS.h"
#include "task.h"
#include "main.h"
#include "cmsis_os.h"

/* USER CODE BEGIN Includes */
#include <stdio.h>
#include <math.h>
#include "usart.h"
#include "robot_params.h"
#include "encoder.h"
#include "motor.h"
#include "motion_profile.h"
#include "encoder_speed.h"
#include "pid.h"
#include "odometry.h"
#include "semphr.h"
#include "touch_rtos.h"
#include "spi.h"
#include "touch_event.h"
#include "xpt2046.h"
#include "ps2xlib.h"
#include "ili9341.h"
//#include "usb_host.h"
//#include "usbh_core.h"
//#include "ps2_pad.h"

#include <rcl/rcl.h>
#include <rcl/error_handling.h>
#include <rclc/rclc.h>
#include <rclc/executor.h>
#include <uxr/client/transport.h>
#include <rmw_microxrcedds_c/config.h>
#include <rmw_microros/rmw_microros.h>

#include <std_msgs/msg/int32.h>

#include <nav_msgs/msg/odometry.h>
#include <geometry_msgs/msg/quaternion.h>
#include <geometry_msgs/msg/vector3.h>
#include <geometry_msgs/msg/pose.h>
#include <geometry_msgs/msg/twist.h>
#include <std_msgs/msg/float64_multi_array.h>
#include <rosidl_runtime_c/string_functions.h>

static rcl_publisher_t odom_pub;
static nav_msgs__msg__Odometry odom_msg;

static float odom_vx  = 0.0f;
static float odom_vy  = 0.0f;
static float odom_vth = 0.0f;
volatile uint32_t last_cmdvel_ms = 0;

//this variables are the set pos or speed from the high level controller

volatile MP_Mode_t modCtrl = MP_MODE_VELOCITY; //default mode
#define POS_CMD_RESYNC_TH    (0.01f)   // position command step that triggers resync (units of position)
#define SPD_CMD_RESYNC_TH    (0.05f)   // speed command step that triggers resync (units of speed)
static inline float fabsf_fast(double x){ return (x < 0.0f) ? -x : x; }

volatile double SetPos1 = 0.0f;
volatile double SetPos2 = 0.0f;
volatile double SetSpeed1 = 0.0f;
volatile double SetSpeed2 = 0.0f;

volatile int g_activeCell = -1;   // biến dùng cho update lcd
static uint8_t s_prevPressed = 0;

static volatile uint8_t pid_update_pending = 0;  //biến dùng để update PID từ ROS
static SemaphoreHandle_t pid_mutex;  //kỹ thuật cho phép tạm thời lock trong quá trình thay đổi biến PID, tránh bị cập nhật nửa chừng

static uint16_t lastX=0, lastY=0;

volatile uint16_t touch_x = 0;
volatile uint16_t touch_y = 0;
volatile uint8_t  touch_pressed = 0;

typedef struct {
    uint16_t x, y, w, h;
    const char* label;
    uint8_t id;
} UICell_t;

static inline int pointInRect(uint16_t px, uint16_t py, const UICell_t* r)
{
    return (px >= r->x) && (px < r->x + r->w) &&
           (py >= r->y) && (py < r->y + r->h);
}
enum {
    CELL_PWM1 = 0,
    CELL_PWM2,
    CELL_ENC1,
    CELL_ENC2,
    CELL_V1,
    CELL_V2,
    CELL_FIGURE,
    CELL_CONTROLLER,
    CELL_ODOMX,
    CELL_ODOMY,
    CELL_YAW,
    CELL_SETTING_PID,
    CELL_COUNT
};
static void uiBuildCellsFromLocLCD(void)
{
	static UICell_t g_cells[CELL_COUNT];
    uint16_t W = lcdGetWidth();
    uint16_t H = lcdGetHeight();

    // giống hệt locLCD()
    uint16_t M  = 6;
    uint16_t GX = M;
    uint16_t GY = 22;
    uint16_t GW = W - 2*M;
    uint16_t GH = H - GY - M;

    uint16_t CW = GW / 3;
    uint16_t RH = GH / 4;

    #define CELL_X(c) (GX + (c)*CW)
    #define CELL_Y(r) (GY + (r)*RH)

    // Cột 1
    g_cells[CELL_PWM1] = (UICell_t){ CELL_X(0), CELL_Y(0), CW, RH, "PWM1", CELL_PWM1 };
    g_cells[CELL_PWM2] = (UICell_t){ CELL_X(0), CELL_Y(1), CW, RH, "PWM2", CELL_PWM2 };
    g_cells[CELL_ENC1] = (UICell_t){ CELL_X(0), CELL_Y(2), CW, RH, "Enc1", CELL_ENC1 };
    g_cells[CELL_ENC2] = (UICell_t){ CELL_X(0), CELL_Y(3), CW, RH, "Enc2", CELL_ENC2 };

    // Cột 2
    g_cells[CELL_V1] = (UICell_t){ CELL_X(1), CELL_Y(0), CW, RH, "V1", CELL_V1 };
    g_cells[CELL_V2] = (UICell_t){ CELL_X(1), CELL_Y(1), CW, RH, "V2", CELL_V2 };
    g_cells[CELL_FIGURE]     = (UICell_t){ CELL_X(1), CELL_Y(2), CW, RH, "Figure", CELL_FIGURE };
    g_cells[CELL_CONTROLLER] = (UICell_t){ CELL_X(1), CELL_Y(3), CW, RH, "Controller", CELL_CONTROLLER };

    // Cột 3
    g_cells[CELL_ODOMX] = (UICell_t){ CELL_X(2), CELL_Y(0), CW, RH, "Odom X", CELL_ODOMX };
    g_cells[CELL_ODOMY] = (UICell_t){ CELL_X(2), CELL_Y(1), CW, RH, "Odom Y", CELL_ODOMY };
    g_cells[CELL_YAW]   = (UICell_t){ CELL_X(2), CELL_Y(2), CW, RH, "Yaw",   CELL_YAW };
    g_cells[CELL_SETTING_PID] = (UICell_t){ CELL_X(2), CELL_Y(3), CW, RH, "Setting PID", CELL_SETTING_PID };

    #undef CELL_X
    #undef CELL_Y
}

static const UICell_t g_cells[CELL_COUNT] = {
    { 0,   0, 160, 120, "ENC1", CELL_ENC1 },
    {160,  0, 160, 120, "ENC2", CELL_ENC2 },
};

typedef struct {
  uint32_t tick;
  uint8_t  id;
  uint16_t buttons;
  uint8_t  lx, ly, rx, ry;
  uint8_t  ok;
  uint8_t  analog;
} PS2X_State;

static PS2X_Handle ps2;

// Shared snapshot for other tasks
static PS2X_State g_ps2_state;
static osMutexId_t g_ps2_mutex;

static inline float clampf(float x, float lo, float hi) {
    if (x < lo) return lo;
    if (x > hi) return hi;
    return x;
}

static inline int is_pressed(uint16_t buttons, uint16_t mask) {
    return (buttons & mask) ? 1 : 0;
}

//bien dung de cap nhat du lieu len locLCD
typedef struct {
  int32_t enc1, enc2;
  float   v1, v2;
} EncData_t;

typedef struct {
  float x, y, yaw;
} OdomData_t;

typedef struct {
  float pwm1, pwm2;
} MotorData_t;

// dữ liệu hiện tại
static EncData_t   g_encData;
static OdomData_t  g_odomData;
static MotorData_t g_motorData;

// sequence numbers (odd = đang ghi, even = xong)
static volatile uint32_t g_encSeq   = 0;
static volatile uint32_t g_odomSeq  = 0;
static volatile uint32_t g_motorSeq = 0;

// memory barrier (CMSIS)
#ifndef __DMB
#define __DMB() __asm volatile ("dmb 0xF":::"memory")
#endif

/* USER CODE END Includes */

/* USER CODE BEGIN PTD */
static inline void EncData_Publish(int32_t enc1, int32_t enc2, float v1, float v2);
static inline void OdomData_Publish(float x, float y, float yaw);
static inline void MotorData_Publish(float pwm1, float pwm2);

bool cubemx_transport_open(struct uxrCustomTransport * transport);
bool cubemx_transport_close(struct uxrCustomTransport * transport);
size_t cubemx_transport_write(struct uxrCustomTransport* transport, const uint8_t * buf, size_t len, uint8_t * err);
size_t cubemx_transport_read(struct uxrCustomTransport* transport, uint8_t* buf, size_t len, int timeout, uint8_t* err);

void * microros_allocate(size_t size, void * state);
void microros_deallocate(void * pointer, void * state);
void * microros_reallocate(void * pointer, size_t size, void * state);
void * microros_zero_allocate(size_t number_of_elements, size_t size_of_element, void * state);
/* USER CODE END PTD */

/* USER CODE BEGIN PD */
static void microros_odom_init(rcl_node_t * node);
static void microros_publish_odom(void);
static void cmdvel_cb(const void * msgin);
static void pid_cb(const void * msgin);
static inline uint32_t millis_void(void);
/* USER CODE END PD */

/* Definitions for defaultTask */
osThreadId_t defaultTaskHandle;
const osThreadAttr_t defaultTask_attributes = {
  .name = "defaultTask",
  .stack_size = 3000 * 4,
  .priority = (osPriority_t) osPriorityNormal,
};

/* USER CODE BEGIN FunctionPrototypes */
osThreadId_t encoderTaskHandle;
osThreadId_t motorTaskHandle;
//osThreadId_t uartTaskHandle
osThreadId_t odometryTaskHandle;
osThreadId_t touchTaskHandle;
//osThreadId_t UsbHostTaskHandle;
osThreadId_t PS2TaskHandle;
osThreadId_t LCDTaskHandle;
osThreadId_t teleopTaskHandle;
osThreadId_t motionTaskHandle;

const osThreadAttr_t encoderTask_attributes = {
  .name       = "EncoderTask",
  .priority   = (osPriority_t) osPriorityHigh,
  .stack_size = 256 * 4
};

const osThreadAttr_t motorTask_attributes = {
  .name       = "MotorTask",
  .priority   = (osPriority_t) osPriorityHigh,
  .stack_size = 256 * 4
};

//const osThreadAttr_t uartTask_attributes = {
//  .name       = "UartTask",
//  .priority   = (osPriority_t) osPriorityLow,
//  .stack_size = 256 * 4
//};

const osThreadAttr_t odometryTask_attributes = {
  .name       = "OdometryTask",
  .priority   = (osPriority_t) osPriorityHigh,
  .stack_size = 256 * 4
};

static const osThreadAttr_t touchTask_attributes = {
      .name = "TouchTask",
      .stack_size = 512 * 4,              // bytes
      .priority = (osPriority_t) osPriorityBelowNormal
};

//const osThreadAttr_t UsbHostTask_attributes = {
//  .name = "UsbHostTask",
//  .stack_size = 1024 * 4,     // 4KB stack (đủ an toàn)
//  .priority = (osPriority_t) osPriorityNormal
//};
//
const osThreadAttr_t PS2Task_attributes = {
  .name       = "PS2Task",
  .stack_size = 512 * 4,   // 2KB stack (đủ cho parse HID)
  .priority   = (osPriority_t) osPriorityNormal
};

const osThreadAttr_t teleopTask_attributes = {
  .name = "TeleopTask",
  .priority = (osPriority_t) osPriorityNormal,
  .stack_size = 512 * 4   // bytes (512 words if you think in words; here it's bytes)
};

const osThreadAttr_t lcdTask_attributes = {
  .name = "lcdTask",
  .stack_size = 1024,
  .priority = (osPriority_t) osPriorityLow  // UI để Low là hợp lý
};

const osThreadAttr_t motionTask_attributes = {
  .name = "motionTask",
  .stack_size = 512 * 4,
  .priority = (osPriority_t) osPriorityNormal  // UI để Low là hợp lý
};

void StartUITask(void *argument);

void EncoderTask(void *argument);
void MotorControlTask(void *argument);
//void UartTask(void *argument);
void OdometryTask(void *argument);
void MotionTask(void *argument);
void TouchTask(void *argument);
//void StartUsbHostTask(void *argument);
void StartPS2Task(void *argument);
void StartLCDTask(void *argument);
void StartTeleopTask(void *argument);
/* USER CODE END FunctionPrototypes */

void StartDefaultTask(void *argument);

void MX_FREERTOS_Init(void); /* (MISRA C 2004 rule 8.1) */

void MX_FREERTOS_Init(void) {
  /* USER CODE BEGIN Init */
  pid_mutex = xSemaphoreCreateMutex();
  g_ps2_mutex = osMutexNew(NULL);

  encoderTaskHandle = osThreadNew(EncoderTask, NULL, &encoderTask_attributes);
  motorTaskHandle   = osThreadNew(MotorControlTask, NULL, &motorTask_attributes);
//  uartTaskHandle    = osThreadNew(UartTask, NULL, &uartTask_attributes);
  odometryTaskHandle = osThreadNew(OdometryTask, NULL, &odometryTask_attributes);

  touchTaskHandle = osThreadNew(TouchTask_Start, NULL, &touchTask_attributes);
//  UsbHostTaskHandle = osThreadNew(StartUsbHostTask, NULL, &UsbHostTask_attributes);
  PS2TaskHandle = osThreadNew(StartPS2Task, NULL, &PS2Task_attributes);
  teleopTaskHandle = osThreadNew(StartTeleopTask, NULL, &teleopTask_attributes);
  LCDTaskHandle = osThreadNew(StartLCDTask, NULL, &lcdTask_attributes);
  teleopTaskHandle = osThreadNew(StartTeleopTask, NULL, &teleopTask_attributes);
  motionTaskHandle = osThreadNew(MotionTask, NULL, &motionTask_attributes);
  /* USER CODE END Init */

  /* Create the thread(s) */
  /* creation of defaultTask */
  defaultTaskHandle = osThreadNew(StartDefaultTask, NULL, &defaultTask_attributes);

}

/* USER CODE BEGIN Application */
void StartDefaultTask(void *argument)
{

  HAL_GPIO_WritePin(GPIOB, GPIO_PIN_0, GPIO_PIN_SET); // LED1 sáng luôn
  // ==== micro-ROS transport config ====
  rmw_uros_set_custom_transport(
    true,
    (void *) &huart3,
    cubemx_transport_open,
    cubemx_transport_close,
    cubemx_transport_write,
    cubemx_transport_read);

  // ==== Allocator FreeRTOS ====
  rcl_allocator_t freeRTOS_allocator = rcutils_get_zero_initialized_allocator();
  freeRTOS_allocator.allocate      = microros_allocate;
  freeRTOS_allocator.deallocate    = microros_deallocate;
  freeRTOS_allocator.reallocate    = microros_reallocate;
  freeRTOS_allocator.zero_allocate = microros_zero_allocate;

  if (!rcutils_set_default_allocator(&freeRTOS_allocator)) {
      printf("Error on default allocators (line %d)\n", __LINE__);
  }

  // ==== micro-ROS core ====
  rclc_support_t support;
  rcl_allocator_t allocator;
  rcl_node_t node;
  rcl_subscription_t sub_cmdvel;
  rcl_subscription_t sub_pid;
  geometry_msgs__msg__Twist msg_cmdvel;
  std_msgs__msg__Float64MultiArray msg_pid;
  rclc_executor_t executor;

  allocator = rcl_get_default_allocator();

  // init_options + context
  rclc_support_init(&support, 0, NULL, &allocator);

  // create node
  rclc_node_init_default(&node, "stm32_odom_node", "", &support);

  // init odom publisher
  microros_odom_init(&node);

  // ==== create subscription /cmd_vel ====
  rclc_subscription_init_default(
      &sub_cmdvel,
      &node,
      ROSIDL_GET_MSG_TYPE_SUPPORT(geometry_msgs, msg, Twist),
      "cmd_vel"
  );

  // ==== create subscription /pid_tunning ====
  rclc_subscription_init_default(
      &sub_pid,
      &node,
      ROSIDL_GET_MSG_TYPE_SUPPORT(std_msgs, msg, Float64MultiArray),
      "pid_tuning"
  );

  // ==== init executor và add sub_cmdvel vào ====
  rclc_executor_init(&executor, &support.context, 2, &allocator);
  rclc_executor_add_subscription(
      &executor,
      &sub_cmdvel,
      &msg_cmdvel,
      &cmdvel_cb,
      ON_NEW_DATA
  );

  rclc_executor_add_subscription(
      &executor,
      &sub_pid,
      &msg_pid,
      &pid_cb,
      ON_NEW_DATA
  );

  // ====== Vòng lặp publish /odom mỗi 10 ms + xử lý /cmd_vel ======
  float last_x     = odom_x;
  float last_y     = odom_y;
  float last_theta = odom_theta;

  const uint32_t period_ms = 10;
  const float    dt        = 0.010f;   // 10 ms
  const uint64_t spin_timeout_ns = 2ULL * 1000000ULL; // 2 ms

  for(;;)
  {
	//Đọc trạng thái touch
	touch_x = g_touchState.x;
	touch_y = g_touchState.y;
	touch_pressed = g_touchState.pressed;

    // Đọc odometry (do task khác đã update odom_x/y/theta)
    float curr_x     = odom_x;
    float curr_y     = odom_y;
    float curr_theta = odom_theta;

    float dx  = curr_x     - last_x;
    float dy  = curr_y     - last_y;
    float dth = curr_theta - last_theta;

    odom_vx  = dx  / dt;
    odom_vy  = dy  / dt;
    odom_vth = dth / dt;

    last_x     = curr_x;
    last_y     = curr_y;
    last_theta = curr_theta;

    // Publish /odom
    microros_publish_odom();

    // Xử lý /cmd_vel (gọi callback nếu có data mới)
    rclc_executor_spin_some(&executor, spin_timeout_ns);

    osDelay(period_ms);
  }
}

void EncoderTask(void *argument)
{
	const TickType_t period = pdMS_TO_TICKS(ENCODER_PERIOD_MS);
	TickType_t lastWake = xTaskGetTickCount();

  for(;;)
  {
    // Đọc count mở rộng
	g_encCount1 = Encoder_GetCount(ENCODER_1);
    g_encCount2 = Encoder_GetCount(ENCODER_2);

    g_speed1_mps = Encoder_GetSpeed_mps(ENCODER_1,DT_TIME);
    g_speed2_mps = Encoder_GetSpeed_mps(ENCODER_2,DT_TIME);

    CurSpeed1 = g_speed1_mps;
    CurSpeed2 = g_speed2_mps;

    EncData_Publish(g_encCount1, g_encCount2, g_speed1_mps, g_speed2_mps);

    //CurPos1 = Encoder_GetPosition_m(ENCODER_1);
    //CurPos2 = Encoder_GetPosition_m(ENCODER_2);

    // Tính số vòng quay của motor (vòng)
    //g_revCount1 = (float)g_encCount1 / TICKS_PER_REV;
    //g_revCount2 = (float)g_encCount2 / TICKS_PER_REV;

    vTaskDelayUntil(&lastWake, period);
  }
}

void MotorControlTask(void *argument)
{
	const TickType_t period = pdMS_TO_TICKS(MOTORCONTROL_PERIOD_MS);
	TickType_t lastWake = xTaskGetTickCount();

	for (;;)
	    {
			//update thông số PID nếu có thay đổi
			if (pid_update_pending)
			{
				if (pid_mutex) xSemaphoreTake(pid_mutex, pdMS_TO_TICKS(2));

				PID_SetTunings(&SpeedPID1, Kp1, Ki1, Kd1);
				PID_SetTunings(&SpeedPID2, Kp2, Ki2, Kd2);
				PID_SetTunings(&PosPID1, Kp1, Ki1, Kd1);
				PID_SetTunings(&PosPID2, Kp2, Ki2, Kd2);

				pid_update_pending = 0;

				if (pid_mutex) xSemaphoreGive(pid_mutex);
			}

			if (modCtrl == MP_MODE_POSITION) {
				PID_Compute(&PosPID1);
				PID_Compute(&PosPID2);
				MotorData_Publish(PosPIDOut1, PosPIDOut2);  //update PWM data for LCD display
				Motor_SetSpeed(MOTOR_1,PosPIDOut1);
				Motor_SetSpeed(MOTOR_2,PosPIDOut2);
			} else {
				PID_Compute(&SpeedPID1);
				PID_Compute(&SpeedPID2);
				MotorData_Publish(SpeedPIDOut1, SpeedPIDOut2);  //update PWM data for LCD display
				Motor_SetSpeed(MOTOR_1,SpeedPIDOut1);
				Motor_SetSpeed(MOTOR_2,SpeedPIDOut2);
			}

//			if (millis_void() - last_cmdvel_ms > 500) {
//			    // hơn 500ms không nhận được lệnh -> dừng robot
//				PosPIDOut1 = 0;
//				PosPIDOut2 = 0;
//				SpeedPIDOut1 = 0;
//				SpeedPIDOut2 = 0;
//				Motor_SetSpeed(MOTOR_1,SpeedPIDOut1);
//				Motor_SetSpeed(MOTOR_2,SpeedPIDOut2);
//			}

			vTaskDelayUntil(&lastWake, period);
	    }
}

//void UartTask(void *argument)
//{
//	const TickType_t period = pdMS_TO_TICKS(UART_PERIOD_MS);
//	TickType_t lastWake = xTaskGetTickCount();
//
//    char buf[64];
//
//    for(;;)
//    {
//        int len = snprintf(buf, sizeof(buf),
//                          "%.3f %.3f\r\n",
//                          g_speed1_mps,
//                          g_speed2_mps);
//
//        HAL_UART_Transmit(&huart3, (uint8_t*)buf, len, 10);
//
//        vTaskDelayUntil(&lastWake, period);
//    }
//}

void OdometryTask(void *argument)
{
	const TickType_t period = pdMS_TO_TICKS(ODOMETRY_PERIOD_MS);
	TickType_t lastWake = xTaskGetTickCount();

    for (;;)
    {
        Odometry_Update();
        OdomData_Publish(odom_x, odom_y, odom_theta);

        vTaskDelayUntil(&lastWake, period);
    }
}

void yaw_to_quaternion(float yaw, geometry_msgs__msg__Quaternion *q)
{
    q->x = 0.0;
    q->y = 0.0;
    q->z = sinf(yaw * 0.5f);
    q->w = cosf(yaw * 0.5f);
}

static void microros_odom_init(rcl_node_t * node)
{
    nav_msgs__msg__Odometry__init(&odom_msg);

    rclc_publisher_init_default(
        &odom_pub,
        node,
        ROSIDL_GET_MSG_TYPE_SUPPORT(nav_msgs, msg, Odometry),
        "odomfromSTM32"
    );

    rosidl_runtime_c__String__assign(&odom_msg.header.frame_id, "odom");
    rosidl_runtime_c__String__assign(&odom_msg.child_frame_id, "base_footprint");
}

static void microros_publish_odom(void)
{
    uint64_t now_ms = rmw_uros_epoch_millis();
    int32_t  sec    = (int32_t)(now_ms / 1000ULL);
    uint32_t nsec   = (uint32_t)((now_ms % 1000ULL) * 1000000ULL);

    // header
    odom_msg.header.stamp.sec     = sec;
    odom_msg.header.stamp.nanosec = nsec;

    // pose
    odom_msg.pose.pose.position.x = odom_x;
    odom_msg.pose.pose.position.y = odom_y;
    odom_msg.pose.pose.position.z = 0.0f;

    yaw_to_quaternion(odom_theta, &odom_msg.pose.pose.orientation);

    // twist
    odom_msg.twist.twist.linear.x  = odom_vx;
    odom_msg.twist.twist.linear.y  = odom_vy;
    odom_msg.twist.twist.angular.z = odom_vth;

    rcl_ret_t rc = rcl_publish(&odom_pub, &odom_msg, NULL);
    (void)rc;  // để compiler khỏi báo unused-variable
}

static inline uint32_t millis_void(void)
{
    return HAL_GetTick();
}

// ===== Callback /cmd_vel: tính DesiredSpeed1/2 cho PID =====
static void cmdvel_cb(const void * msgin)
{
    const geometry_msgs__msg__Twist *m = (const geometry_msgs__msg__Twist *) msgin;

    float v = m->linear.x;   // m/s
    float w = m->angular.z;  // rad/s

    // diff-drive: v_r = v + w*L/2 ; v_l = v - w*L/2
    float v_r = v + (w * WHEEL_BASE_M * 0.5f);
    float v_l = v - (w * WHEEL_BASE_M * 0.5f);

    DesiredSpeed1 = v_r;
    DesiredSpeed2 = v_l;

    last_cmdvel_ms = millis_void();
}

//hàm callback khi nhận được data PID từ ROS
static void pid_cb(const void * msgin)
{
    const std_msgs__msg__Float64MultiArray *m =
        (const std_msgs__msg__Float64MultiArray *)msgin;

    // cần đủ 6 phần tử
    if (m->data.size < 6) return;

    if (pid_mutex) xSemaphoreTake(pid_mutex, pdMS_TO_TICKS(2));

    Kp1 = m->data.data[0];
    Ki1 = m->data.data[1];
    Kd1 = m->data.data[2];
    Kp2 = m->data.data[3];
    Ki2 = m->data.data[4];
    Kd2 = m->data.data[5];

    pid_update_pending = 1;

    if (pid_mutex) xSemaphoreGive(pid_mutex);
}

void MotionTask(void *argument)
{
	const TickType_t period = pdMS_TO_TICKS(MOTORCONTROL_PERIOD_MS);
	TickType_t lastWake = xTaskGetTickCount();

	MP_Config_t mp_cfg1, mp_cfg2;
	MP_State_t  mp_state1, mp_state2;

    mp_cfg1.dt      = DT_TIME;     // 5 ms
    mp_cfg1.vmax    = MAXSPEED;   // your units
    mp_cfg1.amax    = MAXACC;
    mp_cfg1.vel_eps = 0.01f * MAXSPEED; // tune
    mp_cfg1.pos_eps = 0.001f;          // tune (depends on units)

    mp_cfg2.dt      = DT_TIME;     // 5 ms
    mp_cfg2.vmax    = MAXSPEED;   // your units
    mp_cfg2.amax    = MAXACC;
    mp_cfg2.vel_eps = 0.01f * MAXSPEED; // tune
    mp_cfg2.pos_eps = 0.001f;          // tune (depends on units)

    // Initialize using current measured state:
    MP_Init(&mp_state1, CurPos1, CurSpeed1);
    MP_Init(&mp_state2, CurPos2, CurSpeed2);

    int   prevMode = modCtrl;

    float prevSetPos1 = SetPos1, prevSetPos2 = SetPos2;
    float prevSetSpd1 = SetSpeed1, prevSetSpd2 = SetSpeed2;

    for (;;)
    {
    	 // ---- Snapshot inputs (avoid reading changing globals mid-loop) ----
    	int   mode = modCtrl;
        float curPos1 = CurPos1, curPos2 = CurPos2;
        float curSpd1 = CurSpeed1, curSpd2 = CurSpeed2;

        float setPos1 = SetPos1, setPos2 = SetPos2;
        float setSpd1 = SetSpeed1, setSpd2 = SetSpeed2;

        // ---- Determine whether to re-seed planner state (ONE-TIME) ----
        uint8_t modeChanged = (mode != prevMode);

        uint8_t posCmdJump =
            (fabsf_fast(setPos1 - prevSetPos1) > POS_CMD_RESYNC_TH) ||
            (fabsf_fast(setPos2 - prevSetPos2) > POS_CMD_RESYNC_TH);

        uint8_t spdCmdJump =
            (fabsf_fast(setSpd1 - prevSetSpd1) > SPD_CMD_RESYNC_TH) ||
            (fabsf_fast(setSpd2 - prevSetSpd2) > SPD_CMD_RESYNC_TH);

        // Choose resync conditions based on mode
        uint8_t needResync = modeChanged;

        if (mode == MP_MODE_POSITION) {
            needResync = needResync || posCmdJump;
        } else {
            needResync = needResync || spdCmdJump;
        }

        if (needResync) {
            // Re-seed once from measured state so profile starts from reality
            mp_state1.pos_ref = curPos1;
            mp_state1.vel_ref = curSpd1;   // set to measured if your speed is OK; otherwise set to mp_state1.vel_ref
            mp_state2.pos_ref = curPos2;
            mp_state2.vel_ref = curSpd2;
        }

        // ---- Step profile ----
        MP_Output_t ref1, ref2;

        if (modCtrl == MP_MODE_POSITION) {
        	ref1 = MP_StepPosition(&mp_cfg1, &mp_state1, setPos1);
        	ref2 = MP_StepPosition(&mp_cfg2, &mp_state2, setPos2);
            DesiredPos1 = ref1.pos_next;
            DesiredPos2 = ref2.pos_next;
        } else {
        	ref1 = MP_StepVelocity(&mp_cfg1, &mp_state1, setSpd1);
        	ref2 = MP_StepVelocity(&mp_cfg2, &mp_state2, setSpd2);
            DesiredSpeed1 = ref1.vel_next;
            DesiredSpeed2 = ref2.vel_next;
        }

        // ---- Save previous command/mode for next loop ----
		prevMode = mode;
		prevSetPos1 = setPos1;  prevSetPos2 = setPos2;
		prevSetSpd1 = setSpd1;  prevSetSpd2 = setSpd2;

        // v_ref goes into your PID controller later
        // PID_Update(v_ref, measured_speed);

        vTaskDelayUntil(&lastWake, period);
    }
}

//void StartUsbHostTask(void *argument)
//{
//  for(;;)
//  {
//    USBH_Process(&hUsbHostFS);
//    osDelay(1);
//  }
//}
//
void StartPS2Task(void *argument)
{
  (void)argument;

  // Init library (HAL-based, not RTOS-aware)
  PS2X_Init(&ps2, &hspi2);

  // Configure controller: analog + rumble enabled
  bool cfg_ok = PS2X_ConfigGamepad(&ps2, true, true);

  for (;;)
  {
    // Poll controller
    bool ok = cfg_ok && PS2X_ReadGamepad(&ps2, 0, 0);

    // Build snapshot
    PS2X_State st;
    st.tick   = osKernelGetTickCount();
    st.ok     = ok ? 1 : 0;
    st.id     = ps2.id;
    st.buttons= ps2.buttons;
    st.analog = ps2.analog_enabled ? 1 : 0;
    st.rx     = ps2.analog[PSS_RX];
    st.ry     = ps2.analog[PSS_RY];
    st.lx     = ps2.analog[PSS_LX];
    st.ly     = ps2.analog[PSS_LY];

    // Publish snapshot for other tasks
    if (osMutexAcquire(g_ps2_mutex, 2) == osOK) {
      g_ps2_state = st;
      osMutexRelease(g_ps2_mutex);
    }

    // Poll period
    osDelay(10);   // 10ms is typical; adjust if you want
  }
}

void StartTeleopTask(void *argument)
{
    (void)argument;

    for (;;)
    {
        // ---- snapshot controller state ----
        PS2X_State st;
        bool got = false;
        if (osMutexAcquire(g_ps2_mutex, 2) == osOK) {
            st = g_ps2_state;
            osMutexRelease(g_ps2_mutex);
            got = true;
        }

        uint32_t now = osKernelGetTickCount();

        // Default lock
        float v_cmd = 0.0f;
        float w_cmd = 0.0f;
        bool enabled = false;

        if (got && st.ok) {
            // timeout check
            uint32_t age = now - st.tick;
            if (age <= PS2_TIMEOUT_MS) {

                // L1 enable
                if (is_pressed(st.buttons, PSB_L1)) {
                    enabled = true;

                    // ---- decide analog vs d-pad ----
                    int16_t rx = (int16_t)st.rx - 128;
                    int16_t ry = (int16_t)st.ry - 128;

                    if (abs(rx) < STICK_DEADBAND) rx = 0;
                    if (abs(ry) < STICK_DEADBAND) ry = 0;

                    bool analog_active = (rx != 0) || (ry != 0);

                    if (analog_active) {
                        // Analog mode: proportional
                        float rx_n = (float)rx / 127.0f;      // -1..1
                        float ry_n = (float)ry / 127.0f;      // -1..1

                        // Forward: usually pushing up gives ry negative => invert
                        v_cmd = (-ry_n) * V_MAX;
                        w_cmd = ( rx_n) * W_MAX;

                    } else {
                        // D-pad mode: only one effective
                        bool up    = is_pressed(st.buttons, PSB_UP);
                        bool down  = is_pressed(st.buttons, PSB_DOWN);
                        bool left  = is_pressed(st.buttons, PSB_LEFT);
                        bool right = is_pressed(st.buttons, PSB_RIGHT);

                        // Priority choice (simple):
                        if (up && !down && !left && !right) {
                            v_cmd = +V_STEP;  w_cmd = 0.0f;
                        } else if (down && !up && !left && !right) {
                            v_cmd = -V_STEP;  w_cmd = 0.0f;
                        } else if (left && !up && !down && !right) {
                            v_cmd = 0.0f;     w_cmd = -W_STEP;
                        } else if (right && !up && !down && !left) {
                            v_cmd = 0.0f;     w_cmd = +W_STEP;
                        } else {
                            // none or multiple => stop (safer)
                            v_cmd = 0.0f;     w_cmd = 0.0f;
                        }
                    }
                }
            }
        }

        // If not enabled or timeout => lock (0,0)
        if (!enabled) {
            v_cmd = 0.0f;
            w_cmd = 0.0f;
        }

        // ---- convert cmd_vel to wheel linear speeds ----
        float v_r = v_cmd + (w_cmd * WHEEL_BASE_M * 0.5f);
        float v_l = v_cmd - (w_cmd * WHEEL_BASE_M * 0.5f);

        // Optional clamp per wheel to V_MAX
        v_r = clampf(v_r, -V_MAX, +V_MAX);
        v_l = clampf(v_l, -V_MAX, +V_MAX);

        // Publish to planner
        SetSpeed1 = v_l;   // left
        SetSpeed2 = v_r;   // right

        osDelay(10); // teleop update at 10ms is fine
    }
}

static inline void EncData_Publish(int32_t enc1, int32_t enc2, float v1, float v2)
{
  g_encSeq++; __DMB();
  g_encData.enc1 = enc1;
  g_encData.enc2 = enc2;
  g_encData.v1   = v1;
  g_encData.v2   = v2;
  __DMB(); g_encSeq++;
}

static inline void OdomData_Publish(float x, float y, float yaw)
{
  g_odomSeq++; __DMB();
  g_odomData.x   = x;
  g_odomData.y   = y;
  g_odomData.yaw = yaw;
  __DMB(); g_odomSeq++;
}

static inline void MotorData_Publish(float pwm1, float pwm2)
{
  g_motorSeq++; __DMB();
  g_motorData.pwm1 = pwm1;
  g_motorData.pwm2 = pwm2;
  __DMB(); g_motorSeq++;
}

static inline void EncData_Read(EncData_t* out)
{
  uint32_t s1, s2;
  do {
    s1 = g_encSeq; __DMB();
    *out = g_encData; __DMB();
    s2 = g_encSeq;
  } while ((s1 != s2) || (s1 & 1u));
}

static inline void OdomData_Read(OdomData_t* out)
{
  uint32_t s1, s2;
  do {
    s1 = g_odomSeq; __DMB();
    *out = g_odomData; __DMB();
    s2 = g_odomSeq;
  } while ((s1 != s2) || (s1 & 1u));
}

static inline void MotorData_Read(MotorData_t* out)
{
  uint32_t s1, s2;
  do {
    s1 = g_motorSeq; __DMB();
    *out = g_motorData; __DMB();
    s2 = g_motorSeq;
  } while ((s1 != s2) || (s1 & 1u));
}

static void lcdUpdateCell2Lines(uint16_t cx, uint16_t cy, uint16_t cw, uint16_t ch,
                                const char* l1, const char* l2,
                                uint16_t color, uint16_t bg,
                                uint16_t charW, uint16_t fontH, uint16_t P)
{
    int m = (int)((cw - 2*P) / charW); if (m < 1) m = 1;

    int len1 = (int)strlen(l1); if (len1 > m) len1 = m;
    int len2 = (int)strlen(l2); if (len2 > m) len2 = m;

    int w1 = len1 * (int)charW;
    int w2 = len2 * (int)charW;
    int wMax = (w1 > w2) ? w1 : w2;

    int16_t x = (int16_t)cx + (int16_t)((cw - wMax)/2);
    int16_t y = (int16_t)cy + (int16_t)((ch - 2*(int16_t)fontH)/2);

    if (x < (int16_t)cx + (int16_t)P) x = (int16_t)cx + (int16_t)P;
    if (y < (int16_t)cy + (int16_t)P) y = (int16_t)cy + (int16_t)P;

    // clear vùng 2 dòng
    lcdFillRect(cx + 1, (uint16_t)y, cw - 2, 2*fontH, bg);

    lcdSetTextColor(color, bg);
    lcdSetCursor((unsigned short)x, (unsigned short)y);
    lcdPrintf("%.*s", len1, l1);

    lcdSetCursor((unsigned short)x, (unsigned short)(y + fontH));
    lcdPrintf("%.*s", len2, l2);
}

static void lcdUpdateAllValues_FromSnapshots(void)
{
    // --- đọc snapshot (nhanh, không block) ---
    EncData_t   enc;
    OdomData_t  od;
    MotorData_t mot;

    EncData_Read(&enc);
    OdomData_Read(&od);
    MotorData_Read(&mot);

    // --- tính grid y hệt locLCD() ---
    uint16_t W = lcdGetWidth();
    uint16_t H = lcdGetHeight();

    uint16_t fontH = lcdGetTextFont()->Height;
    uint16_t charW = lcdGetTextFont()->Width;
    if (charW == 0) charW = 8;

    uint16_t M  = 6;
    uint16_t GX = M;
    uint16_t GY = 22;
    uint16_t GW = W - 2*M;
    uint16_t GH = H - GY - M;

    uint16_t CW = GW / 3;
    uint16_t RH = GH / 4;
    uint16_t P  = 6;

    #define CELL_X(c) (GX + (c)*CW)
    #define CELL_Y(r) (GY + (r)*RH)

    // --- format string ---
    char s_pwm1[16], s_pwm2[16];
    char s_enc1[16], s_enc2[16];
    char s_v1[16],   s_v2[16];
    char s_x[16],    s_y[16], s_yaw[16];

    snprintf(s_pwm1, sizeof(s_pwm1), "%.2f", mot.pwm1);
    snprintf(s_pwm2, sizeof(s_pwm2), "%.2f", mot.pwm2);
    snprintf(s_enc1, sizeof(s_enc1), "%ld", (long)enc.enc1);
    snprintf(s_enc2, sizeof(s_enc2), "%ld", (long)enc.enc2);
    snprintf(s_v1,   sizeof(s_v1),   "%.2f", enc.v1);
    snprintf(s_v2,   sizeof(s_v2),   "%.2f", enc.v2);
    snprintf(s_x,    sizeof(s_x),    "%.2f", od.x);
    snprintf(s_y,    sizeof(s_y),    "%.2f", od.y);
    snprintf(s_yaw,  sizeof(s_yaw),  "%.2f", od.yaw);

    // --- update các ô (đúng như UI của bạn) ---
    lcdUpdateCell2Lines(CELL_X(0), CELL_Y(0), CW, RH, "PWM1",  s_pwm1, COLOR_CYAN, COLOR_BLACK, charW, fontH, P);
    lcdUpdateCell2Lines(CELL_X(0), CELL_Y(1), CW, RH, "PWM2",  s_pwm2, COLOR_CYAN, COLOR_BLACK, charW, fontH, P);
    lcdUpdateCell2Lines(CELL_X(0), CELL_Y(2), CW, RH, "Enc1",  s_enc1, COLOR_CYAN, COLOR_BLACK, charW, fontH, P);
    lcdUpdateCell2Lines(CELL_X(0), CELL_Y(3), CW, RH, "Enc2",  s_enc2, COLOR_CYAN, COLOR_BLACK, charW, fontH, P);

    lcdUpdateCell2Lines(CELL_X(1), CELL_Y(0), CW, RH, "V1",    s_v1,   COLOR_CYAN, COLOR_BLACK, charW, fontH, P);
    lcdUpdateCell2Lines(CELL_X(1), CELL_Y(1), CW, RH, "V2",    s_v2,   COLOR_CYAN, COLOR_BLACK, charW, fontH, P);

    lcdUpdateCell2Lines(CELL_X(2), CELL_Y(0), CW, RH, "Odom X", s_x,    COLOR_CYAN, COLOR_BLACK, charW, fontH, P);
    lcdUpdateCell2Lines(CELL_X(2), CELL_Y(1), CW, RH, "Odom Y", s_y,    COLOR_CYAN, COLOR_BLACK, charW, fontH, P);
    lcdUpdateCell2Lines(CELL_X(2), CELL_Y(2), CW, RH, "Yaw",    s_yaw,  COLOR_CYAN, COLOR_BLACK, charW, fontH, P);

    #undef CELL_X
    #undef CELL_Y
}

void StartLCDTask(void *argument)
{
    (void)argument;

    //locLCD(); // vẽ UI tĩnh 1 lần

    const uint32_t period_ms = 50; // 40Hz
    uint32_t tick = osKernelGetTickCount();

// for (;;)
//    {
//        tick += period_ms;
//        uint32_t t0 = osKernelGetTickCount();
//        lcdUpdateAllValues_FromSnapshots();
//        uint32_t t1 = osKernelGetTickCount();
//        uint32_t dt_ticks = t1 - t0;
//        osDelayUntil(tick);
//    }
    for (;;)
    {
        osDelay(500);   // tạm thời không update gì
    }

}
/* USER CODE END Application */
